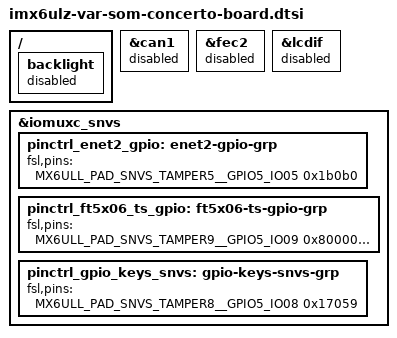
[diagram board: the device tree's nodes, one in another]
// SPDX-License-Identifier: GPL-2.0+
/*
 * Copyright (C) 2026 Variscite Ltd. - https://www.variscite.com
 */

#include "imx6ul-imx6ull-var-som-concerto-board.dtsi"

/ {
	backlight {
		status = "disabled";
	};
};

&can1 {
	status = "disabled";
};

&fec2 {
	status = "disabled";
};

&lcdif {
	status = "disabled";
};

&iomuxc_snvs {
	pinctrl_enet2_gpio: enet2-gpio-grp {
		fsl,pins = <
			MX6ULL_PAD_SNVS_TAMPER5__GPIO5_IO05	0x1b0b0
		>;
	};

	pinctrl_ft5x06_ts_gpio: ft5x06-ts-gpio-grp {
		fsl,pins = <
			MX6ULL_PAD_SNVS_TAMPER9__GPIO5_IO09	0x80000000
		>;
	};

	pinctrl_gpio_keys_snvs: gpio-keys-snvs-grp {
		fsl,pins = <
			MX6ULL_PAD_SNVS_TAMPER8__GPIO5_IO08	0x17059
		>;
	};
};
